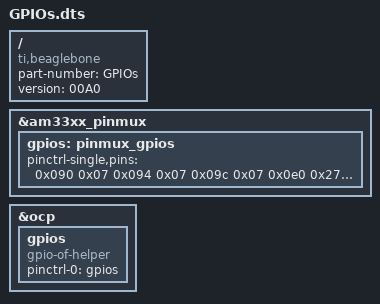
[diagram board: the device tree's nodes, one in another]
/dts-v1/;
/plugin/;

/{
    compatible = "ti,beaglebone", "ti,beaglebone-black";

    part-number = "GPIOs";
    version = "00A0";

    fragment@0 {
        target = <&am33xx_pinmux>;
        __overlay__ {
            gpios: pinmux_gpios{
                pinctrl-single,pins = <
		    // LEDs: 
		    0x090 0x07    // P8_07 output, pulldown, mux-mode 7 
		    0x094 0x07    // P8_08 output, pulldown, mux-mode 7 
		    0x09c 0x07    // P8_09 output, pulldown, mux-mode 7 
		    // Buttons:
		    0x0e0 0x27	  // P8_27 input, pulldown, mmode 7 GPIO2_22
		    0x0e8 0x27    // P8_28 input, pulldown, mmode 7 GPIO2_24
		    0x0e4 0x27    // P8_29 input, pulldown, mmode 7 GPIO2_23
		    0x0ec 0x27    // p8_30 input, pulldown, mmode 7 GPIO2_25
                >;
            };
        };
    };

    fragment@1 {
        target = <&ocp>;
        __overlay__ {
            gpios {
                compatible = "gpio-of-helper";
                pinctrl-names = "default";
                pinctrl-0 = <&gpios>;
            };
        };
    };
};

